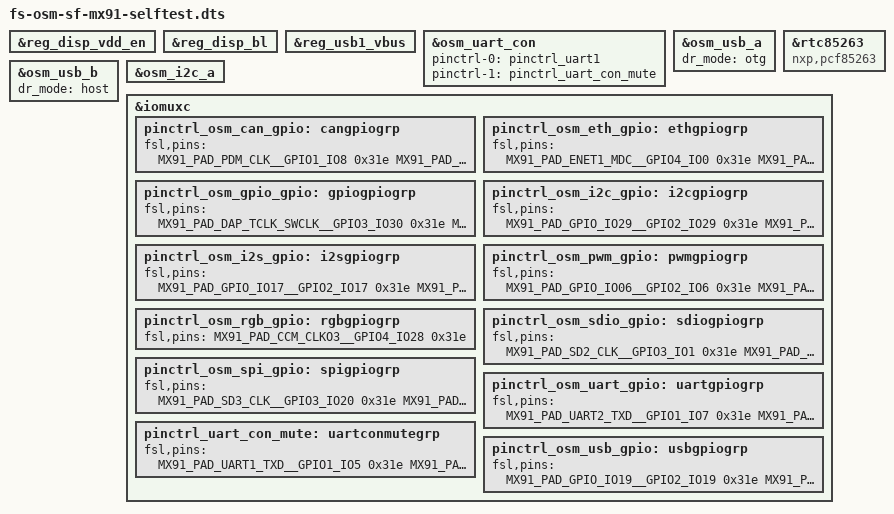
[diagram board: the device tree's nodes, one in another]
// SPDX-License-Identifier: GPL-2.0
/*
* Copyright 2024 F&S Elektronik Systeme GmbH
*
* This program is free software; you can redistribute it and/or modify
* it under the terms of the GNU General Public License version 2 as
* published by the Free Software Foundation.
*
* This program is distributed in the hope that it will be useful,
* but WITHOUT ANY WARRANTY; without even the implied warranty of
* MERCHANTABILITY or FITNESS FOR A PARTICULAR PURPOSE.  See the
* GNU General Public License for more details.
*/

#include "fs-osm-sf-mx91.dtsi"

&reg_disp_vdd_en {
	/delete-property/ gpio;
	/delete-property/ pinctrl-names;
	/delete-property/ pinctrl-0;
};

&reg_disp_bl {
	/delete-property/ gpio;
	/delete-property/ pinctrl-names;
	/delete-property/ pinctrl-0;
};

&reg_usb1_vbus {
	/delete-property/ gpio;
	/delete-property/ pinctrl-names;
	/delete-property/ pinctrl-0;
};

&osm_uart_con {
	pinctrl-names = "default", "mute";
	pinctrl-0 = <&pinctrl_uart1>;
	pinctrl-1 = <&pinctrl_uart_con_mute>;
	status = "okay";
};

&osm_usb_a {
    dr_mode = "otg";
    // hnp-disable;
	// srp-disable;
	// adp-disable;
    status = "okay";
};

&osm_usb_b {
    dr_mode = "host";
    status = "okay";
};

#define gCAN_A_TX			<&gpio1 8 0>
#define gCAN_A_RX			<&gpio1 9 0>

#define gCAN_B_TX			<&gpio3 28 0>
#define gCAN_B_RX			<&gpio3 31 0>

#define gETH_MDC			<&gpio4 0 0>
#define gETH_MDIO			<&gpio4 1 0>
#define gETH_A_MII_TX_CLK	<&gpio4 7 0>
#define gETH_A_MII_TX_EN	<&gpio4 6 0>
#define gETH_A_MII_TXD0		<&gpio4 5 0>
#define gETH_A_MII_TXD1		<&gpio4 4 0>
#define gETH_A_MII_TXD2		<&gpio4 3 0>
#define gETH_A_MII_TXD3		<&gpio4 2 0>
#define gETH_A_MII_RX_CLK	<&gpio4 9 0>
#define gETH_A_MII_RX_DV	<&gpio4 8 0>
#define gETH_A_MII_RXD0		<&gpio4 10 0>
#define gETH_A_MII_RXD1		<&gpio4 11 0>
#define gETH_A_MII_RXD2		<&gpio4 12 0>
#define gETH_A_MII_RXD3		<&gpio4 13 0>

#define gETH_B_MDC			<0>
#define gETH_B_MDIO			<0>
#define gETH_B_MII_TX_CLK	<&gpio4 21 0>
#define gETH_B_MII_TX_EN	<&gpio4 20 0>
#define gETH_B_MII_TXD0		<&gpio4 19 0>
#define gETH_B_MII_TXD1		<&gpio4 18 0>
#define gETH_B_MII_TXD2		<&gpio4 17 0>
#define gETH_B_MII_TXD3		<&gpio4 16 0>
#define gETH_B_MII_RX_CLK	<&gpio4 23 0>
#define gETH_B_MII_RX_DV	<&gpio4 22 0>
#define gETH_B_MII_RXD0		<&gpio4 24 0>
#define gETH_B_MII_RXD1		<&gpio4 25 0>
#define gETH_B_MII_RXD2		<&gpio4 26 0>
#define gETH_B_MII_RXD3		<&gpio4 27 0>

#define gGPIO_A_0			<&gpio3 30 0>
#define gGPIO_A_1			<&gpio3 29 0>
#define gGPIO_A_2			<0>
#define gGPIO_A_3			<0>
#define gGPIO_A_4			<0>
#define gGPIO_A_5			<0>

#define gGPIO_B_0			<0>
#define gGPIO_B_1			<0>
#define gGPIO_B_2			<0>
#define gGPIO_B_3			<0>
#define gGPIO_B_4			<0>
#define gGPIO_B_5			<0>
#define gGPIO_B_6			<0>
#define gGPIO_B_7			<0>

#define gGPIO_C_0			<0>
#define gGPIO_C_1			<0>
#define gGPIO_C_2			<0>
#define gGPIO_C_3			<0>
/* GPIO_C_4 */
#define gDISP_VDD_EN		<&gpio4 15 0>
/* GPIO_C_5 */
#define gDISP_BL_EN			<&gpio2 7 0>
/* GPIO_C_6 */
#define gCAM_A_PWR			<&gpio3 27 0>
/* GPIO_C_7 */
#define gCAM_A_RST			<&gpio4 28 0>

#define gI2C_B_SCL			<&gpio2 29 0>
#define gI2C_B_SDA			<&gpio2 28 0>

#define gI2C_CAM_CK			<&gpio2 23 0>
#define gI2C_CAM_DAT		<&gpio2 22 0>

#define gI2S_MCLK			<&gpio2 17 0>
#define gI2S_LRCLK			<&gpio2 26 0>
#define gI2S_BITCLK			<&gpio2 16 0>
#define gI2S_A_DATA_OUT		<&gpio2 21 0>
#define gI2S_A_DATA_IN		<&gpio2 20 0>
#define gI2S_B_DATA_OUT		<0>
#define gI2S_B_DATA_IN		<0>

#define gDISP_BL_PWM		<&gpio2 6 0>
#define gPWM_1				<&gpio2 4 0>
#define gPWM_2				<&gpio2 5 0>
#define gPWM_3				<0>
#define gPWM_4				<0>
#define gPWM_5				<0>

#define gRGB_R0				<0>
#define gRGB_R1				<0>
#define gRGB_R2				<0>
#define gRGB_R3				<0>
#define gRGB_R4				<0>
#define gRGB_R5				<0>
#define gRGB_B0				<0>
#define gRGB_B1				<0>
#define gRGB_B2				<0>
#define gRGB_B3				<0>
#define gRGB_B4				<0>
#define gRGB_B5				<0>
#define gRGB_G0				<0>
#define gRGB_G1				<0>
#define gRGB_G2				<0>
#define gRGB_G3				<0>
#define gRGB_G4				<0>
#define gRGB_G5				<0>
#define gRGB_CLK			<0>
#define gRGB_DISP			<0>
#define gRGB_DE				<0>
#define gRGB_HSYNC			<0>
#define gRGB_VSYNC			<0>
#define gRGB_RESET			<0>

#define gSDIO_A_CLK			<&gpio3 1 0>
#define gSDIO_A_CMD			<&gpio3 2 0>
#define gSDIO_A_D0			<&gpio3 3 0>
#define gSDIO_A_D1			<&gpio3 4 0>
#define gSDIO_A_D2			<&gpio3 5 0>
#define gSDIO_A_D3			<&gpio3 6 0>
#define gSDIO_A_CD			<&gpio3 0 0>
#define gSDIO_A_WP			<&gpio2 25 0>
#define gSDIO_A_PWR_EN		<&gpio3 7 0>

#define gSDIO_B_CLK			<0>
#define gSDIO_B_CMD			<0>
#define gSDIO_B_D0			<0>
#define gSDIO_B_D1			<0>
#define gSDIO_B_D2			<0>
#define gSDIO_B_D3			<0>
#define gSDIO_B_D4			<0>
#define gSDIO_B_D5			<0>
#define gSDIO_B_D6			<0>
#define gSDIO_B_D7			<0>
#define gSDIO_B_CD			<0>
#define gSDIO_B_WP			<0>
#define gSDIO_B_PWR_EN		<0>

#define gSPI_A_SCK			<&gpio3 20 0>
#define gSPI_A_IO0			<&gpio3 22 0>
#define gSPI_A_IO1			<&gpio3 23 0>
#define gSPI_A_IO2			<&gpio3 24 0>
#define gSPI_A_IO3			<&gpio3 25 0>
#define gSPI_A_CS0			<&gpio3 21 0>
/* GPIO_A_6 */
#define gSPI_A_CS1			<&gpio4 14 0>

#define gSPI_B_SCK			<&gpio2 11 0>
#define gSPI_B_SDO			<&gpio2 10 0>
#define gSPI_B_SDI			<&gpio2 9 0>
#define gSPI_B_CS0			<&gpio2 8 0>
/* GPIO_A_7 */
#define gSPI_B_CS1			<&gpio2 24 0>

#define gUART_A_TX			<&gpio1 7 0>
#define gUART_A_RX			<&gpio1 6 0>
#define gUART_A_RTS			<&gpio1 13 0>
#define gUART_A_CTS			<&gpio1 12 0>

#define gUART_B_TX			<&gpio2 0 0>
#define gUART_B_RX			<&gpio2 1 0>
#define gUART_B_RTS			<&gpio2 3 0>
#define gUART_B_CTS			<&gpio2 2 0>

#define gUART_C_TX			<&gpio2 14 0>
#define gUART_C_RX			<&gpio2 15 0>

#define gUART_D_TX			<&gpio2 12 0>
#define gUART_D_RX			<&gpio2 13 0>

#define gUSB_A_EN			<&gpio2 19 0>
#define gUSB_A_OC			<&gpio1 10 0>

&rtc85263 {
	compatible = "nxp,pcf85263";
};

&osm_i2c_a {
	status = "okay";
};

&iomuxc{
	pinctrl_osm_can_gpio: cangpiogrp{
		fsl,pins = <
			/* CAN_A */
			MX91_PAD_PDM_CLK__GPIO1_IO8			0x31e
			MX91_PAD_PDM_BIT_STREAM0__GPIO1_IO9	0x31e
			/* CAN_B */
			MX91_PAD_DAP_TDI__GPIO3_IO28			0x31e
			MX91_PAD_DAP_TDO_TRACESWO__GPIO3_IO31	0x31e
		>;
	};

	pinctrl_osm_eth_gpio: ethgpiogrp {
		fsl,pins = <
			/* ETH_A */
			MX91_PAD_ENET1_MDC__GPIO4_IO0		0x31e
			MX91_PAD_ENET1_MDIO__GPIO4_IO1		0x31e
			MX91_PAD_ENET1_TXC__GPIO4_IO7		0x31e
			MX91_PAD_ENET1_TX_CTL__GPIO4_IO6	0x31e
			MX91_PAD_ENET1_TD0__GPIO4_IO5		0x31e
			MX91_PAD_ENET1_TD1__GPIO4_IO4		0x31e
			MX91_PAD_ENET1_TD2__GPIO4_IO3		0x31e
			/* NOTE: 
			 * MX91_PAD_ENET1_TD3__GPIO4_IO3 is actually MX91_PAD_ENET1_TD3__GPIO4_IO2, see iMX91RM
			 */
			MX91_PAD_ENET1_TD3__GPIO4_IO3		0x31e
			MX91_PAD_ENET1_RXC__GPIO4_IO9		0x31e
			MX91_PAD_ENET1_RX_CTL__GPIO4_IO8	0x31e
			MX91_PAD_ENET1_RD0__GPIO4_IO10		0x31e
			MX91_PAD_ENET1_RD1__GPIO4_IO11		0x31e
			MX91_PAD_ENET1_RD2__GPIO4_IO12		0x31e
			MX91_PAD_ENET1_RD3__GPIO4_IO13		0x31e
			/* ETH_B */
			MX91_PAD_ENET2_TXC__GPIO4_IO21		0x31e
			MX91_PAD_ENET2_TX_CTL__GPIO4_IO20	0x31e
			MX91_PAD_ENET2_TD0__GPIO4_IO19		0x31e
			MX91_PAD_ENET2_TD1__GPIO4_IO18		0x31e
			MX91_PAD_ENET2_TD2__GPIO4_IO17		0x31e
			MX91_PAD_ENET2_TD3__GPIO4_IO16		0x31e
			MX91_PAD_ENET2_RXC__GPIO4_IO23		0x31e
			MX91_PAD_ENET2_RX_CTL__GPIO4_IO22	0x31e
			MX91_PAD_ENET2_RD0__GPIO4_IO24		0x31e
			MX91_PAD_ENET2_RD1__GPIO4_IO25		0x31e
			MX91_PAD_ENET2_RD2__GPIO4_IO26		0x31e
			MX91_PAD_ENET2_RD3__GPIO4_IO27		0x31e
		>;
	};

	pinctrl_osm_gpio_gpio: gpiogpiogrp {
		fsl,pins = <
			/* GPIO_A */
			/* 0 */ MX91_PAD_DAP_TCLK_SWCLK__GPIO3_IO30	0x31e
			/* 1 */ MX91_PAD_DAP_TMS_SWDIO__GPIO3_IO29	0x31e
			/* 2 */ /* optional to UART_C_RX */
			/* 3 */ /* optional to UART_C_TX */
			/* 4 */ /* optional to UART_D_RX */
			/* 5 */ /* optional to UART_D_TX */
			/* 6 */ /* optional to SPI_A_CS1 */
			/* 7 */ /* optional to SPI_B_CS1 */
			/* GPIO_B */
			/* 0-7 NC */
			/* GPIO_C */
			/* 0-3 NC */
			/* 4 DISP_VDD_EN */	MX91_PAD_ENET2_MDIO__GPIO4_IO15	0x31e
			/* 5 DISP_BL_EN */	MX91_PAD_GPIO_IO07__GPIO2_IO7	0x31e
			/* 6 CAM_A_PWR */	MX91_PAD_CCM_CLKO2__GPIO3_IO27	0x31e
			/* 7 CAM_A_RST */	MX91_PAD_CCM_CLKO3__GPIO4_IO28	0x31e
		>;
	};

	pinctrl_osm_i2c_gpio: i2cgpiogrp {
		fsl,pins = <
			/* I2C_B */
			MX91_PAD_GPIO_IO29__GPIO2_IO29		0x31e
			MX91_PAD_GPIO_IO28__GPIO2_IO28		0x31e
			/* I2C_CAM */
			MX91_PAD_GPIO_IO23__GPIO2_IO23		0x31e
			MX91_PAD_GPIO_IO22__GPIO2_IO22		0x31e
		>;
	};

	pinctrl_osm_i2s_gpio: i2sgpiogrp {
		fsl,pins = <
			/* I2S */
			MX91_PAD_GPIO_IO17__GPIO2_IO17		0x31e
			MX91_PAD_GPIO_IO26__GPIO2_IO26		0x31e
			MX91_PAD_GPIO_IO16__GPIO2_IO16		0x31e
			/* I2S_A */
			MX91_PAD_GPIO_IO21__GPIO2_IO21		0x31e
			MX91_PAD_GPIO_IO20__GPIO2_IO20		0x31e
			/* I2S_B */
			/* NC */
		>;
	};

	pinctrl_osm_pwm_gpio: pwmgpiogrp {
		fsl,pins = <
			/* PWM */
			/* 0 DISP_BL_PWM */	MX91_PAD_GPIO_IO06__GPIO2_IO6	0x31e
			/* 1 */ MX91_PAD_GPIO_IO04__GPIO2_IO4	0x31e
			/* 2 */ MX91_PAD_GPIO_IO05__GPIO2_IO5	0x31e
			/* 3-5 NC */
		>;
	};

	pinctrl_osm_rgb_gpio: rgbgpiogrp {
		fsl,pins = <
			/* RGB */
			/* NC */
			/* supress pinfunc warning */
			/* 7 CAM_A_RST */	MX91_PAD_CCM_CLKO3__GPIO4_IO28	0x31e
		>;
	};

	pinctrl_osm_sdio_gpio: sdiogpiogrp {
		fsl,pins = <
			/* SDIO_A */
			MX91_PAD_SD2_CLK__GPIO3_IO1		0x31e
			MX91_PAD_SD2_CMD__GPIO3_IO2		0x31e
			MX91_PAD_SD2_DATA0__GPIO3_IO3		0x31e
			MX91_PAD_SD2_DATA1__GPIO3_IO4		0x31e
			MX91_PAD_SD2_DATA2__GPIO3_IO5		0x31e
			MX91_PAD_SD2_DATA3__GPIO3_IO6		0x31e
			MX91_PAD_SD2_CD_B__GPIO3_IO0		0x31e
			MX91_PAD_GPIO_IO25__GPIO2_IO25		0x31e
			MX91_PAD_SD2_RESET_B__GPIO3_IO7	0x31e
			/* SDIO_B */
			/* NC */
		>;
	};

	pinctrl_osm_spi_gpio: spigpiogrp {
		fsl,pins = <
			/* SPI_A */
			MX91_PAD_SD3_CLK__GPIO3_IO20		0x31e
			MX91_PAD_SD3_DATA0__GPIO3_IO22		0x31e
			MX91_PAD_SD3_DATA1__GPIO3_IO23		0x31e
			MX91_PAD_SD3_DATA2__GPIO3_IO24		0x31e
			MX91_PAD_SD3_DATA3__GPIO3_IO25		0x31e
			MX91_PAD_SD3_CMD__GPIO3_IO21		0x31e
			MX91_PAD_ENET2_MDC__GPIO4_IO14		0x31e
			/* SPI_B */
			MX91_PAD_GPIO_IO11__GPIO2_IO11		0x31e
			MX91_PAD_GPIO_IO10__GPIO2_IO10		0x31e
			MX91_PAD_GPIO_IO09__GPIO2_IO9		0x31e
			MX91_PAD_GPIO_IO08__GPIO2_IO8		0x31e
			MX91_PAD_GPIO_IO24__GPIO2_IO24		0x31e
		>;
	};

	pinctrl_osm_uart_gpio: uartgpiogrp{
		fsl,pins = <
			/* UART_A */
			MX91_PAD_UART2_TXD__GPIO1_IO7		0x31e
			MX91_PAD_UART2_RXD__GPIO1_IO6		0x31e
			MX91_PAD_SAI1_TXD0__GPIO1_IO13		0x31e
			MX91_PAD_SAI1_TXC__GPIO1_IO12		0x31e
			/* UART_B */
			MX91_PAD_GPIO_IO00__GPIO2_IO0		0x31e
			MX91_PAD_GPIO_IO01__GPIO2_IO1		0x31e
			MX91_PAD_GPIO_IO03__GPIO2_IO3		0x31e
			MX91_PAD_GPIO_IO02__GPIO2_IO2		0x31e
			/* UART_C */
			MX91_PAD_GPIO_IO14__GPIO2_IO14		0x31e
			MX91_PAD_GPIO_IO15__GPIO2_IO15		0x31e
			/* UART_D */
			MX91_PAD_GPIO_IO12__GPIO2_IO12		0x31e
			MX91_PAD_GPIO_IO13__GPIO2_IO13		0x31e
		>;
	};

	pinctrl_uart_con_mute: uartconmutegrp {
		fsl,pins = <
			MX91_PAD_UART1_TXD__GPIO1_IO5			0x31e
			MX91_PAD_UART1_RXD__GPIO1_IO4			0x31e
		>;
	};

	pinctrl_osm_usb_gpio: usbgpiogrp{
		fsl,pins = <
			/* USB_A */
			MX91_PAD_GPIO_IO19__GPIO2_IO19			0x31e
			MX91_PAD_PDM_BIT_STREAM1__GPIO1_IO10	0x31e
		>;
	};
};
